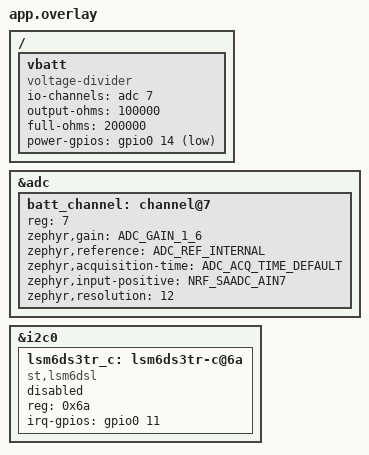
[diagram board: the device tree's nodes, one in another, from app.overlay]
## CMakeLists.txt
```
# SPDX-License-Identifier: Apache-2.0
cmake_minimum_required(VERSION 3.20.0)
find_package(Zephyr REQUIRED HINTS $ENV{ZEPHYR_BASE})
project(SmartBridge)

target_sources(app PRIVATE src/main.c)

if(CONFIG_SMARTBRIDGE_ANT)
  target_sources(app PRIVATE src/ant_bpwr.c)
  target_sources(app PRIVATE src/ant_lev.c)
endif()
```

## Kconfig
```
mainmenu "SmartBridge"

config SMARTBRIDGE_ANT
    bool "Enable ANT+ Bicycle Power (requires ANT+ Adopter access)"
    depends on ANT
    help
      Enable ANT+ Bicycle Power transmission alongside BLE.
      Requires ANT+ Adopter registration at thisisant.com and
      access to the sdk-ant repository.

source "Kconfig.zephyr"
```

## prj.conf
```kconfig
# ANT disabled — BLE only build
CONFIG_SMARTBRIDGE_ANT=n

# ====================== USB Serial ======================
CONFIG_USB_CDC_ACM=y
CONFIG_USB_DEVICE_STACK=y
CONFIG_UART_LINE_CTRL=y
CONFIG_UART_CONSOLE=y

# ====================== Bootloader ======================
# DISABLE MCUBOOT - much simpler for now
# CONFIG_BOOTLOADER_MCUBOOT=n

# ====================== Bluetooth ======================
CONFIG_BT=y
CONFIG_BT_PERIPHERAL=y
CONFIG_BT_MAX_CONN=2
CONFIG_BT_GATT_DYNAMIC_DB=y
CONFIG_BT_DEVICE_NAME="SmartBridge"
CONFIG_BT_DEVICE_NAME_DYNAMIC=y

# ====================== Services ======================
CONFIG_BT_DIS=y
CONFIG_BT_DIS_MANUF="Nilogax"
CONFIG_BT_DIS_MODEL="SmartBridge"
CONFIG_BT_DIS_FW_REV=y
CONFIG_BT_DIS_FW_REV_STR="0.9.2"
CONFIG_BT_BAS=y

# ====================== Peripherals ======================
CONFIG_ADC=y
CONFIG_I2C=y
CONFIG_GPIO=y

# ====================== Logging ======================
CONFIG_PRINTK=y
CONFIG_LOG=y
CONFIG_LOG_DEFAULT_LEVEL=2

# ====================== Memory ======================
CONFIG_MAIN_STACK_SIZE=4096
CONFIG_SYSTEM_WORKQUEUE_STACK_SIZE=4096
CONFIG_HEAP_MEM_POOL_SIZE=8192

CONFIG_LSM6DSL=n
CONFIG_LSM6DSO=n
CONFIG_LSM6DS0=n
```

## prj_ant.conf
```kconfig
# ANT enabled
CONFIG_ANT=y
CONFIG_ANT_EVALUATION_KEY=y
CONFIG_SMARTBRIDGE_ANT=y
CONFIG_ANT_BPWR=y
CONFIG_ANT_KEY_MANAGER=y
CONFIG_ANT_CHANNEL_CONFIG=y

# ====================== USB Serial ======================
CONFIG_USB_CDC_ACM=y
CONFIG_USB_DEVICE_STACK=y
CONFIG_UART_LINE_CTRL=y
CONFIG_UART_CONSOLE=y

# ====================== Bootloader ======================
# DISABLE MCUBOOT - much simpler for now
# CONFIG_BOOTLOADER_MCUBOOT=n

# ====================== Bluetooth ======================
CONFIG_BT=y
CONFIG_BT_PERIPHERAL=y
CONFIG_BT_MAX_CONN=2
CONFIG_BT_GATT_DYNAMIC_DB=y
CONFIG_BT_DEVICE_NAME="SmartBridge"
CONFIG_BT_DEVICE_NAME_DYNAMIC=y

# ====================== Services ======================
CONFIG_BT_DIS=y
CONFIG_BT_DIS_MANUF="Nilogax"
CONFIG_BT_DIS_MODEL="SmartBridge"
CONFIG_BT_DIS_FW_REV=y
CONFIG_BT_DIS_FW_REV_STR="0.9.2"
CONFIG_BT_BAS=y

# ====================== Peripherals ======================
CONFIG_ADC=y
CONFIG_I2C=y
CONFIG_GPIO=y

# ====================== Logging ======================
CONFIG_PRINTK=y
CONFIG_LOG=y
CONFIG_LOG_DEFAULT_LEVEL=2

# ====================== Memory ======================
CONFIG_MAIN_STACK_SIZE=4096
CONFIG_SYSTEM_WORKQUEUE_STACK_SIZE=4096
CONFIG_HEAP_MEM_POOL_SIZE=8192

CONFIG_LSM6DSL=n
CONFIG_LSM6DSO=n
CONFIG_LSM6DS0=n
```

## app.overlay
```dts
/ {
    vbatt: vbatt {
        compatible = "voltage-divider";
        io-channels = <&adc 7>;
        output-ohms = <100000>;
        full-ohms = <200000>;
        power-gpios = <&gpio0 14 GPIO_ACTIVE_LOW>;
    };
};

&adc {
    status = "okay";
    #address-cells = <1>;
    #size-cells = <0>;

    batt_channel: channel@7 {
        reg = <7>;
        zephyr,gain = "ADC_GAIN_1_6";
        zephyr,reference = "ADC_REF_INTERNAL";
        zephyr,acquisition-time = <ADC_ACQ_TIME_DEFAULT>;
        zephyr,input-positive = <NRF_SAADC_AIN7>;
        zephyr,resolution = <12>;
    };
};

&i2c0 {
    status = "okay";
    lsm6ds3tr_c: lsm6ds3tr-c@6a {
        compatible = "st,lsm6dsl";
        reg = <0x6a>;
        irq-gpios = <&gpio0 11 GPIO_ACTIVE_HIGH>;
    };
};

&lsm6ds3tr_c {
    status = "disabled";
};
```

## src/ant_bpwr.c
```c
/*
 * SmartBridge ANT+ Bicycle Power sensor
 */

#ifdef CONFIG_SMARTBRIDGE_ANT

#include <zephyr/kernel.h>
#include <zephyr/logging/log.h>

#include <ant_interface.h>
#include <ant_key_manager.h>
#include <ant_profiles/bpwr/ant_bpwr.h>
#include "ant_common_page_82.h"
#include "version.h"

LOG_MODULE_REGISTER(smartbridge_ant, LOG_LEVEL_INF);

/* ── Channel configuration ───────────────────────────────────────────────── */
#define ANT_BPWR_CHANNEL_NUM    0
#define ANT_BPWR_NETWORK_NUM    0
#define ANT_BPWR_TRANS_TYPE     5

#define ANT_DEVICE_NUMBER_DEFAULT  49

#define ANT_HW_VERSION          1
#define ANT_MFG_ID              255
#define ANT_MODEL_NUM           1
#define ANT_SW_VERSION_MAJOR    10*FW_VERSION_MAJOR + FW_VERSION_MINOR
#define ANT_SW_VERSION_MINOR    FW_VERSION_PATCH
#define ANT_SERIAL_NUM          ((uint32_t)(NRF_FICR->DEVICEADDR[0]))

/*
 * ── Page 82 interleave ────────────────────────────────────────────────────
*/
#define ANT_P82_INTERLEAVE_COUNT   122u

/* Battery voltage thresholds in mV */
#define BATT_THRESH_LOW_MV      3500u
#define BATT_THRESH_CRIT_MV     3200u

/* ── Module state ────────────────────────────────────────────────────────── */
static ant_bpwr_profile_t        bpwr;
static ant_common_page82_data_t  s_page82     = DEFAULT_ANT_COMMON_page82();
static uint32_t                  s_tx_count   = 0;

/* Forward declarations needed by config macros */
static void ant_bpwr_evt_handler(ant_bpwr_profile_t *p_profile,
                                  ant_bpwr_evt_t event);
static void ant_bpwr_calib_handler(ant_bpwr_profile_t *p_profile,
                                    ant_bpwr_page1_data_t *p_page1);

BPWR_SENS_CHANNEL_CONFIG_DEF(bpwr,
    ANT_BPWR_CHANNEL_NUM,
    ANT_BPWR_TRANS_TYPE,
    ANT_DEVICE_NUMBER_DEFAULT,
    ANT_BPWR_NETWORK_NUM);

BPWR_SENS_PROFILE_CONFIG_DEF(bpwr,
    TORQUE_NONE,
    ant_bpwr_calib_handler,
    ant_bpwr_evt_handler);

/* ── Profile event handler ───────────────────────────────────────────────── */
static void ant_bpwr_evt_handler(ant_bpwr_profile_t *p_profile,
                                  ant_bpwr_evt_t event)
{
    ARG_UNUSED(p_profile);
    ARG_UNUSED(event);
}

/* ── Calibration handler ─────────────────────────────────────────────────── */
static void ant_bpwr_calib_handler(ant_bpwr_profile_t *p_profile,
                                    ant_bpwr_page1_data_t *p_page1)
{
    switch (p_page1->calibration_id) {
    case ANT_BPWR_CALIB_ID_MANUAL:
    case ANT_BPWR_CALIB_ID_AUTO:
        p_profile->BPWR_PROFILE_calibration_id     = ANT_BPWR_CALIB_ID_MANUAL_SUCCESS;
        p_profile->BPWR_PROFILE_general_calib_data = 0;
        break;
    default:
        break;
    }
}

/* ── ANT event callback ──────────────────────────────────────────────────── */
static void ant_evt_handler(ant_evt_t *p_ant_evt)
{
    if (p_ant_evt->channel != ANT_BPWR_CHANNEL_NUM) {
        return;
    }

    /*
     * On every ANT_P82_INTERLEAVE_COUNT-th TX event, encode page 82
     * ourselves and skip the library's ant_message_send for that slot.
     */
    if (p_ant_evt->event == EVENT_TX) {
        s_tx_count++;
        if (s_tx_count >= ANT_P82_INTERLEAVE_COUNT) {
            s_tx_count = 0;

            uint8_t buf[ANT_STANDARD_DATA_PAYLOAD_SIZE];
            ant_common_page_82_encode(buf, &s_page82);

            int err = ant_broadcast_message_tx(ANT_BPWR_CHANNEL_NUM,
                                               sizeof(buf), buf);
            if (err) {
                LOG_WRN("Page 82 TX failed (err %d)", err);
            } else {
                LOG_INF("ANT: Page 82 sent (status=%u)", s_page82.battery_status);
            }
            /*
             * Return WITHOUT forwarding to ant_bpwr_sens_evt_handler.
             */
            return;
        }
    }

    /* All other events (including normal EVENT_TX) go to the library */
    ant_bpwr_sens_evt_handler(p_ant_evt, &bpwr);
}

/* ── Public API ──────────────────────────────────────────────────────────── */

int ant_bpwr_setup(void)
{
    int err;

    err = ant_init();
    if (err) {
        LOG_ERR("ant_init failed (err %d)", err);
        return err;
    }
    LOG_INF("ANT version: %s", ANT_VERSION_STRING);

    err = ant_cb_register(ant_evt_handler);
    if (err) {
        LOG_ERR("ant_cb_register failed (err %d)", err);
        return err;
    }

    err = ant_plus_key_set(ANT_BPWR_NETWORK_NUM);
    if (err) {
        LOG_ERR("ant_network_key_set failed (err %d)", err);
        return err;
    }

    err = ant_bpwr_sens_init(&bpwr,
                              BPWR_SENS_CHANNEL_CONFIG(bpwr),
                              BPWR_SENS_PROFILE_CONFIG(bpwr));
    if (err) {
        LOG_ERR("ant_bpwr_sens_init failed (err %d)", err);
        return err;
    }

    uint16_t dev_num = (uint16_t)(NRF_FICR->DEVICEADDR[0] & 0xFFFF);
    ant_channel_id_set(ANT_BPWR_CHANNEL_NUM,
                       dev_num,
                       BPWR_DEVICE_TYPE,
                       ANT_BPWR_TRANS_TYPE);

    bpwr.page_80 = ANT_COMMON_page80(ANT_HW_VERSION,
                                      ANT_MFG_ID,
                                      ANT_MODEL_NUM);
    bpwr.page_81 = ANT_COMMON_page81(ANT_SW_VERSION_MAJOR,
                                      ANT_SW_VERSION_MINOR,
                                      ANT_SERIAL_NUM);

    bpwr.BPWR_PROFILE_auto_zero_status = ANT_BPWR_AUTO_ZERO_OFF;

    err = ant_bpwr_sens_open(&bpwr);
    if (err) {
        LOG_ERR("ant_bpwr_sens_open failed (err %d)", err);
        return err;
    }

    LOG_INF("ANT+ Bicycle Power channel open (device %u)", dev_num);
    return 0;
}

void ant_bpwr_update(uint16_t watts, uint8_t cadence, uint8_t left_pct)
{
    bpwr.BPWR_PROFILE_power_update_event_count++;
    bpwr.BPWR_PROFILE_accumulated_power    += watts;
    bpwr.BPWR_PROFILE_instantaneous_power   = watts;
    bpwr.BPWR_PROFILE_instantaneous_cadence = cadence;

    if (left_pct <= 100) {
        bpwr.BPWR_PROFILE_pedal_power.distribution    = 100u - left_pct;
        bpwr.BPWR_PROFILE_pedal_power.differentiation = 1;
    } else {
        bpwr.page_16.pedal_power.byte = 0xFF;
    }
}

void ant_bpwr_update_battery(uint16_t vbat_mv)
{
    uint8_t coarse = (uint8_t)(vbat_mv / 1000u);
    uint8_t frac   = (uint8_t)(((vbat_mv % 1000u) * 256u) / 1000u);

    uint8_t status;
    if      (vbat_mv < BATT_THRESH_CRIT_MV) { status = ANT_COMMON_PAGE82_BATTERY_STATUS_CRITICAL; }
    else if (vbat_mv < BATT_THRESH_LOW_MV)  { status = ANT_COMMON_PAGE82_BATTERY_STATUS_LOW;      }
    else if (vbat_mv < 3800u)               { status = ANT_COMMON_PAGE82_BATTERY_STATUS_OK;       }
    else if (vbat_mv < 4100u)               { status = ANT_COMMON_PAGE82_BATTERY_STATUS_GOOD;     }
    else                                    { status = ANT_COMMON_PAGE82_BATTERY_STATUS_NEW;      }

    s_page82 = ANT_COMMON_page82(
        0,        /* cumulative_op_time not tracked */
        coarse,
        frac,
        status);

    LOG_INF("Battery: %u mV -> coarse=%u frac=%u", vbat_mv, coarse, frac);
    LOG_INF("Battery status: %u", status);
}

void ant_bpwr_stop(void)
{
    int err = ant_channel_close(ANT_BPWR_CHANNEL_NUM);
    if (err) {
        LOG_WRN("ant_channel_close failed (err %d)", err);
    } else {
        LOG_INF("ANT+ channel closed");
    }
}

void ant_bpwr_start(void)
{
    s_tx_count = 0;
    int err = ant_bpwr_sens_open(&bpwr);
    if (err) {
        LOG_WRN("ant_bpwr_sens_open failed on wake (err %d)", err);
    } else {
        LOG_INF("ANT+ channel reopened");
    }
}

#endif /* CONFIG_SMARTBRIDGE_ANT */
```

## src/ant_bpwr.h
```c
/*
 * SmartBridge ANT+ Bicycle Power interface
 */
#ifndef SMARTBRIDGE_ANT_BPWR_H
#define SMARTBRIDGE_ANT_BPWR_H

#ifdef CONFIG_SMARTBRIDGE_ANT

/**
 * Initialise ANT stack, register the bicycle power sensor channel,
 * and open it. Call once at the top of main() before the main loop.
 * Returns 0 on success, negative error code on failure.
 */
int ant_bpwr_setup(void);

/**
 * Update the transmitted power data. Call every 250 ms alongside
 * the existing BLE send_power() call.
 *
 * @param watts      Instantaneous power (W)
 * @param cadence    Instantaneous cadence (rpm)
 * @param left_pct   Left pedal balance (0-100, >100 = not available)
 */
void ant_bpwr_update(uint16_t watts, uint8_t cadence, uint8_t left_pct);

/**
 * Update ANT+ Page 82 (Battery Status). Call whenever a fresh ADC
 * reading is available — every 60 s is sufficient.
 *
 * @param vbat_mv       Battery voltage in millivolts (e.g. 3700).
 * @param op_time_16s   Cumulative operating time in 16-second units.
 *                      Pass 0 if not tracked.
 */
void ant_bpwr_update_battery(uint16_t vbat_mv);

/**
 * Close the ANT channel. Call from enter_sleep().
 */
void ant_bpwr_stop(void);

/**
 * Re-open the ANT channel. Call from wake_up().
 */
void ant_bpwr_start(void);

#endif /* CONFIG_SMARTBRIDGE_ANT */
#endif /* SMARTBRIDGE_ANT_BPWR_H */
```

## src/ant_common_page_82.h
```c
/*
 * ANT+ Common Page 82 (0x52) - Battery Status
 * Not present in NCS 2.6.0 ANT library.
 *
 * Byte layout:
 *   [0] 0x52  page number
 *   [1] 0xFF  reserved
 *   [2] 0xFF  battery identifier (0xFF = single battery / not used)
 *   [3] op_time bits  0-7
 *   [4] op_time bits  8-15
 *   [5] op_time bits 16-23  (resolution flag NOT used here; kept simple)
 *   [6] fractional voltage  (1/256 V per LSB)
 *   [7] bits 3-0 = coarse voltage (0-14 V; 15 = invalid)
 *       bits 6-4 = battery status
 *       bit    7 = 0 (reserved)
 *
 */
#ifndef ANT_COMMON_PAGE_82_H__
#define ANT_COMMON_PAGE_82_H__

#include <stdint.h>

#ifdef __cplusplus
extern "C" {
#endif

#define ANT_COMMON_PAGE_82  (82u)   ///< Page number (0x52)

/* ── Battery status nibble (bits 6-4 of byte 7) ─────────────────────────── */
#define ANT_COMMON_PAGE82_BATTERY_STATUS_NEW        (1u)
#define ANT_COMMON_PAGE82_BATTERY_STATUS_GOOD       (2u)
#define ANT_COMMON_PAGE82_BATTERY_STATUS_OK         (3u)
#define ANT_COMMON_PAGE82_BATTERY_STATUS_LOW        (4u)
#define ANT_COMMON_PAGE82_BATTERY_STATUS_CRITICAL   (5u)
#define ANT_COMMON_PAGE82_BATTERY_STATUS_INVALID    (7u)

/**
 * @brief Data structure for ANT+ common page 82.
 *
 * coarse_voltage : whole volts (0-14; 15 = invalid)
 * frac_voltage   : fractional volts in units of 1/256 V (0-255)
 *   e.g. 3.9 V → coarse=3, frac=round(0.9×256)=230
 */
typedef struct
{
    uint32_t cumulative_op_time;    ///< Operating time; 0 if not tracked
    uint8_t  coarse_voltage;        ///< Whole volts (0-14; 15 = invalid)
    uint8_t  frac_voltage;          ///< Fractional voltage (1/256 V per LSB)
    uint8_t  battery_status;        ///< ANT_COMMON_PAGE82_BATTERY_STATUS_*
} ant_common_page82_data_t;

/** @brief Zero-initialise page 82 with invalid status. */
#define DEFAULT_ANT_COMMON_page82()         \
    (ant_common_page82_data_t)              \
    {                                       \
        .cumulative_op_time = 0,            \
        .coarse_voltage     = 15,           \
        .frac_voltage       = 0,            \
        .battery_status     = ANT_COMMON_PAGE82_BATTERY_STATUS_INVALID, \
    }

/** @brief Initialise page 82 with specific values. */
#define ANT_COMMON_page82(op_time, coarse, frac, status)    \
    (ant_common_page82_data_t)                              \
    {                                                       \
        .cumulative_op_time = (op_time),                    \
        .coarse_voltage     = (coarse),                     \
        .frac_voltage       = (frac),                       \
        .battery_status     = (status),                     \
    }

/**
 * @brief Encode page 82 into an 8-byte ANT broadcast buffer.
 */
static inline void ant_common_page_82_encode(
        uint8_t * p_buf,
        ant_common_page82_data_t const * p_page_data)
{
    p_buf[0] = ANT_COMMON_PAGE_82;  /* 0x52                          */
    p_buf[1] = 0xFF;                /* reserved                      */
    p_buf[2] = 0xFF;                /* battery identifier: not used  */

    /* Bytes 3-5: 24-bit cumulative operating time, little-endian    */
    p_buf[3] = (uint8_t)(p_page_data->cumulative_op_time);
    p_buf[4] = (uint8_t)(p_page_data->cumulative_op_time >> 8);
    p_buf[5] = (uint8_t)(p_page_data->cumulative_op_time >> 16);

    /* Byte 6: fractional voltage                                     */
    p_buf[6] = p_page_data->frac_voltage;

    /* Byte 7: coarse voltage (bits 3-0), status (bits 6-4), bit7=0  */
    p_buf[7] = (uint8_t)(
        (p_page_data->coarse_voltage  & 0x0Fu) |
        ((p_page_data->battery_status & 0x07u) << 4));
}

#ifdef __cplusplus
}
#endif

#endif /* ANT_COMMON_PAGE_82_H__ */
```

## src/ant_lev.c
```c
#ifdef CONFIG_SMARTBRIDGE_ANT

#include <zephyr/kernel.h>
#include <zephyr/logging/log.h>
#include <ant_interface.h>
#include <ant_parameters.h>
#include <ant_host_init.h>
#include <ant_channel_config.h>
#include <ant_key_manager.h>
#include "version.h"

LOG_MODULE_REGISTER(smartbridge_lev, LOG_LEVEL_INF);

#define ANT_LEV_CHANNEL_NUM     1
#define ANT_LEV_NETWORK_NUM     0
#define ANT_LEV_DEVICE_TYPE     0x14u
#define ANT_LEV_TRANS_TYPE      0x05u
#define ANT_LEV_RF_FREQ         0x39u
#define ANT_LEV_MSG_PERIOD      8192u
#define ANT_LEV_EXT_ASSIGN      0x00u

/* Pages 80/81 */
#define ANT_LEV_HW_REVISION     1
#define ANT_LEV_MFG_ID          63          /* Pretend to be Specialized */
#define ANT_LEV_MODEL_NUM       2
#define ANT_LEV_SERIAL_NUM      ((uint32_t)(NRF_FICR->DEVICEADDR[0]))


#define ANT_LEV_NUM_ASSIST_MODES  4u   /* excluding off */

#define COMMON_PAGE_INTERVAL    40u

/* ── Module state ────────────────────────────────────────────────────────── */
static uint8_t  s_soc_pct     = 0;
static uint8_t  s_assist_mode = 0;   /* internal 0-4 */
static uint8_t  s_assist_pct  = 0;
static uint32_t s_odometer    = 0;   /* 0.01 km units, 24-bit               */
static uint16_t s_speed       = 0;   /* 0.1 km/h units, 12-bit              */
static uint16_t s_range_km    = 0;   /* whole km; 0 = unknown               */
static uint32_t s_msg_count   = 0;

static void lev_ant_evt_handler(ant_evt_t *p_ant_evt);

static const ant_channel_config_t s_lev_channel_cfg = {
    .channel_number    = ANT_LEV_CHANNEL_NUM,
    .channel_type      = CHANNEL_TYPE_MASTER,
    .ext_assign        = ANT_LEV_EXT_ASSIGN,
    .rf_freq           = ANT_LEV_RF_FREQ,
    .transmission_type = ANT_LEV_TRANS_TYPE,
    .device_type       = ANT_LEV_DEVICE_TYPE,
    .device_number     = 0,
    .channel_period    = ANT_LEV_MSG_PERIOD,
    .network_number    = ANT_LEV_NETWORK_NUM,
};

/* ── Travel mode byte helper ─────────────────────────────────────────────── */

static inline uint8_t travel_mode_byte(void)
{
    uint8_t mode = s_assist_mode < 5u ? s_assist_mode : 4u;
    return (uint8_t)((mode & 0x07u) << 3);
}

/* ── Page encoders ───────────────────────────────────────────────────────── */

/*
 * Page 1 – Speed & System Information 1 (Table 5-2)
 *
 * Byte 0: 0x01
 * Byte 1: Temperature state — 0x00 = unknown
 * Byte 2: Travel mode state (Table 5-4)
 * Byte 3: System state — 0x00 = no lights/throttle/signals
 * Byte 4: Gear state   — 0x00 = no gears
 * Byte 5: Error message — 0x00 = no error
 * Byte 6: Speed LSB (12-bit, 0.1 km/h units)
 * Byte 7: Speed MSN (bits 3-0) | 0xF0 (reserved bits 7-4 = 0xF per spec)
 */
static void encode_page1(uint8_t *buf)
{
    uint16_t spd = s_speed & 0x0FFFu;
    buf[0] = 0x01u;
    buf[1] = 0x00u;           /* temperature unknown                        */
    buf[2] = travel_mode_byte();
    buf[3] = 0x00u;           /* system state: nothing supported            */
    buf[4] = 0x00u;           /* gear state: no gears                       */
    buf[5] = 0x00u;           /* no error                                   */
    buf[6] = (uint8_t)(spd & 0xFFu);
    buf[7] = (uint8_t)(0xF0u | ((spd >> 8) & 0x0Fu));
}

/*
 * Page 2 – Speed & Distance Information (Table 5-8)
 *
 * Byte 0: 0x02
 * Byte 1-3: Odometer (24-bit LE, 0.01 km)
 * Byte 4:   Remaining range LSB (12-bit km; 0x000 = unknown)
 * Byte 5:   Remaining range MSN (bits 3-0) | 0xF0 (reserved)
 * Byte 6:   Speed LSB (0.1 km/h, 12-bit)
 * Byte 7:   Speed MSN | 0xF0
 */
static void encode_page2(uint8_t *buf)
{
    uint32_t odo  = s_odometer & 0xFFFFFFu;
    uint16_t rng  = s_range_km & 0x0FFFu;
    uint16_t spd  = s_speed    & 0x0FFFu;
    buf[0] = 0x02u;
    buf[1] = (uint8_t)(odo & 0xFFu);
    buf[2] = (uint8_t)((odo >> 8) & 0xFFu);
    buf[3] = (uint8_t)((odo >> 16) & 0xFFu);
    buf[4] = (uint8_t)(rng & 0xFFu);
    buf[5] = (uint8_t)(0xF0u | ((rng >> 8) & 0x0Fu));
    buf[6] = (uint8_t)(spd & 0xFFu);
    buf[7] = (uint8_t)(0xF0u | ((spd >> 8) & 0x0Fu));
}

/*
 * Page 3 – Speed & System Information 2 (Table 5-10)
 *
 * Byte 0: 0x03
 * Byte 1: Battery SOC — bits 6-0 = %, bit 7 = empty warning
 * Byte 2: Travel mode state (same as page 1)
 * Byte 3: System state — 0x00
 * Byte 4: Gear state   — 0x00
 * Byte 5: % Assist     — 0xFF = unknown, or actual value 0-100
 * Byte 6: Speed LSB (0.1 km/h, 12-bit)
 * Byte 7: Speed MSN | 0xF0
 */
static void encode_page3(uint8_t *buf)
{
    uint8_t soc = s_soc_pct & 0x7Fu;   /* bit 7 = empty warning (set if <5%) */
    if (s_soc_pct < 5u) {
        soc |= 0x80u;
    }
    uint16_t spd = s_speed & 0x0FFFu;
    buf[0] = 0x03u;
    buf[1] = soc;
    buf[2] = travel_mode_byte();
    buf[3] = 0x00u;
    buf[4] = 0x00u;
    buf[5] = s_assist_pct;
    buf[6] = (uint8_t)(spd & 0xFFu);
    buf[7] = (uint8_t)(0xF0u | ((spd >> 8) & 0x0Fu));
}

/*
 * Page 5 – LEV Capabilities (Table 5-12)
 *
 * Byte 0: 0x05
 * Byte 1: 0xFF reserved
 * Byte 2: Travel modes supported — bits 5-3 = num assist, bits 2-0 = num regen
 * Byte 3: Wheel circumference LSB — 0x00 = unknown
 * Byte 4: Wheel circ MSN (bits 3-0) = 0, reserved bits 7-4 = 0xF
 * Bytes 5-7: 0xFF
 */
static void encode_page5(uint8_t *buf)
{
    buf[0] = 0x05u;
    buf[1] = 0xFFu;
    buf[2] = (uint8_t)((ANT_LEV_NUM_ASSIST_MODES & 0x07u) << 3); /* 4 assist, 0 regen */
    buf[3] = 0x00u;   /* wheel circumference unknown                        */
    buf[4] = 0xF0u;   /* MSN=0 (unknown), reserved=0xF                     */
    buf[5] = 0xFFu;
    buf[6] = 0xFFu;
    buf[7] = 0xFFu;
}

/*
 * Page 80 – Manufacturer info (Table 5-17)
 */
static void encode_page80(uint8_t *buf)
{
    buf[0] = 0x50u;
    buf[1] = 0xFFu;
    buf[2] = 0xFFu;
    buf[3] = ANT_LEV_HW_REVISION;
    buf[4] = (uint8_t)(ANT_LEV_MFG_ID & 0xFFu);
    buf[5] = (uint8_t)(ANT_LEV_MFG_ID >> 8);
    buf[6] = (uint8_t)(ANT_LEV_MODEL_NUM & 0xFFu);
    buf[7] = (uint8_t)(ANT_LEV_MODEL_NUM >> 8);
}

/*
 * Page 81 – Product info (Table 5-18)
 */
static void encode_page81(uint8_t *buf)
{
    buf[0] = 0x51u;
    buf[1] = 0xFFu;
    buf[2] = 0xFFu;
    buf[3] = FW_VERSION_MINOR;
    buf[4] = (uint8_t)(ANT_LEV_SERIAL_NUM);
    buf[5] = (uint8_t)(ANT_LEV_SERIAL_NUM >> 8);
    buf[6] = (uint8_t)(ANT_LEV_SERIAL_NUM >> 16);
    buf[7] = (uint8_t)(ANT_LEV_SERIAL_NUM >> 24);
}

/* ── TX rotation ─────────────────────────────────────────────────────────── */
static void lev_send_next(void)
{
    uint8_t buf[ANT_STANDARD_DATA_PAYLOAD_SIZE];
    uint8_t slot = (uint8_t)(s_msg_count % 4u);

    switch (slot) {
    case 0:
        encode_page1(buf);
        break;
    case 1:
        encode_page2(buf);
        break;
    case 2:
        encode_page3(buf);
        break;
    case 3:
    default:
        /*
         * 4th slot rotates: page 5 normally, page 80 every 40 messages,
         * page 81 every 80 messages, then reset.
         * s_msg_count is the count of the message about to be sent (pre-increment).
         */
        if (s_msg_count == COMMON_PAGE_INTERVAL - 1u) {
            encode_page80(buf);
        } else if (s_msg_count == COMMON_PAGE_INTERVAL * 2u - 1u) {
            encode_page81(buf);
        } else {
            encode_page5(buf);
        }
        break;
    }

    s_msg_count++;
    if (s_msg_count >= COMMON_PAGE_INTERVAL * 2u) {
        s_msg_count = 0u;
    }

    int err = ant_broadcast_message_tx(ANT_LEV_CHANNEL_NUM, sizeof(buf), buf);
    if (err) {
        LOG_WRN("LEV TX failed (err %d)", err);
    }
}

/* ── Page 16 decoder (Display → LEV) ────────────────────────────────────── */
/*
 * Page 16 – Display Data (Table 5-14)
*
 * Byte 0: 0x10
 * Byte 1: Wheel circumference LSB  (0xFF = not set by display)
 * Byte 2: Wheel circ MSN / reserved
 * Byte 3: Travel mode (Table 5-4 bits 5-0); 0xFF = not set
 * Byte 4: Display command LSB
 * Byte 5: Display command MSB
 * Byte 6: Manufacturer ID LSB
 * Byte 7: Manufacturer ID MSB
 */
static void handle_page16(const uint8_t *buf)
{
    uint8_t travel_mode = buf[3];
    if (travel_mode == 0xFFu) {
        return;
    }

    /* Extract assist level from bits 5-3 and clamp to our 0-4 range */
    uint8_t requested = (travel_mode >> 3) & 0x07u;
    if (requested > 4u) requested = 4u;
    s_assist_mode = requested;
    LOG_INF("Page 16: display requested assist %u", requested);
}

static void lev_ant_evt_handler(ant_evt_t *p_ant_evt)
{
    if (p_ant_evt->channel != ANT_LEV_CHANNEL_NUM) {
        return;
    }

    switch (p_ant_evt->event) {
    case EVENT_TX:
        lev_send_next();
        break;

    case EVENT_RX:
        /*
         * The Garmin may send page 16 as an acknowledged message on the
         * reverse channel. The payload is in p_ant_evt->message.ANT_MESSAGE_aucPayload.
         */
        if (p_ant_evt->message.ANT_MESSAGE_aucPayload[0] == 0x10u) {
            handle_page16(p_ant_evt->message.ANT_MESSAGE_aucPayload);
        }
        break;

    case EVENT_RX_FAIL:
        /* Normal on a master channel — slave didn't respond, not an error */
        break;

    case EVENT_CHANNEL_CLOSED:
        LOG_INF("LEV channel closed");
        break;

    default:
        break;
    }
}


int ant_lev_setup(void)
{
    int err;

    uint16_t dev_num = (uint16_t)((NRF_FICR->DEVICEADDR[0] & 0xFFFF) ^ 0x0001u);
    if (dev_num == 0u) {
        dev_num = 1u;
    }

    err = ant_cb_register(lev_ant_evt_handler);
    if (err) {
        LOG_ERR("ant_cb_register (LEV) failed (err %d)", err);
        return err;
    }

    ant_channel_config_t cfg = s_lev_channel_cfg;
    cfg.device_number = dev_num;

    err = ant_channel_init(&cfg);
    if (err) {
        LOG_ERR("ant_channel_init (LEV) failed (err %d)", err);
        return err;
    }

    /* Seed TX buffer with page 1 before opening */
    uint8_t buf[ANT_STANDARD_DATA_PAYLOAD_SIZE];
    encode_page1(buf);
    err = ant_broadcast_message_tx(ANT_LEV_CHANNEL_NUM, sizeof(buf), buf);
    if (err) {
        LOG_ERR("LEV initial TX failed (err %d)", err);
        return err;
    }

    err = ant_channel_open(ANT_LEV_CHANNEL_NUM);
    if (err) {
        LOG_ERR("ant_channel_open (LEV) failed (err %d)", err);
        return err;
    }

    LOG_INF("ANT+ LEV channel open (device %u, mfg %u)", dev_num, ANT_LEV_MFG_ID);
    return 0;
}

void ant_lev_update(uint8_t battery_soc_pct, uint8_t assist_mode, uint8_t assist_pct,
                    uint32_t odometer_cm, uint16_t speed_dmkh, uint16_t range_km)
{
    s_soc_pct     = (battery_soc_pct <= 100u) ? battery_soc_pct : 100u;
    s_assist_mode = assist_mode;
    s_assist_pct  = assist_pct;
    s_odometer    = odometer_cm  & 0xFFFFFFu;
    s_speed       = speed_dmkh   & 0x0FFFu;
    s_range_km    = range_km     & 0x0FFFu;
}

void ant_lev_stop(void)
{
    int err = ant_channel_close(ANT_LEV_CHANNEL_NUM);
    if (err) {
        LOG_WRN("ant_channel_close (LEV) failed (err %d)", err);
    } else {
        LOG_INF("ANT+ LEV channel closed");
    }
}

void ant_lev_start(void)
{
    s_msg_count = 0;

    uint8_t buf[ANT_STANDARD_DATA_PAYLOAD_SIZE];
    encode_page1(buf);
    ant_broadcast_message_tx(ANT_LEV_CHANNEL_NUM, sizeof(buf), buf);

    int err = ant_channel_open(ANT_LEV_CHANNEL_NUM);
    if (err) {
        LOG_WRN("ant_channel_open (LEV) failed on wake (err %d)", err);
    } else {
        LOG_INF("ANT+ LEV channel reopened");
    }
}

#endif /* CONFIG_SMARTBRIDGE_ANT */
```

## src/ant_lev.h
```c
#ifndef SMARTBRIDGE_ANT_LEV_H
#define SMARTBRIDGE_ANT_LEV_H

#ifdef CONFIG_SMARTBRIDGE_ANT

#include <stdint.h>

/**
 * Initialise and open the ANT+ LEV sensor channel.
 * Call once after ant_bpwr_setup().
 * Returns 0 on success, negative error code on failure.
 */
int ant_lev_setup(void);

/**
 * Update LEV data. Call whenever values change (e.g. every 750 ms).
 *
 * @param battery_soc_pct   Battery state of charge 0-100 %
 * @param assist_mode       Internal assist level 0-4
 * @param assist_pct        Assistance level 0-100 % (motor / total power)
 * @param odometer_cm       Odometer in 0.01 km units (metres / 10), 24-bit
 * @param speed_dmkh        Speed in 0.1 km/h units (0.01 km/h value / 10), 12-bit
 * @param range_km          Estimated remaining range in whole km; 0 = unknown
 */
void ant_lev_update(uint8_t battery_soc_pct, uint8_t assist_mode, uint8_t assist_pct,
                    uint32_t odometer_cm, uint16_t speed_dmkh, uint16_t range_km);

/**
 * Close the LEV channel. Call from enter_sleep().
 */
void ant_lev_stop(void);

/**
 * Re-open the LEV channel. Call from wake_up().
 */
void ant_lev_start(void);

#endif /* CONFIG_SMARTBRIDGE_ANT */
#endif /* SMARTBRIDGE_ANT_LEV_H */
```

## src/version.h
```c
#pragma once
#define FW_VERSION_MAJOR 0
#define FW_VERSION_MINOR 9
#define FW_VERSION_PATCH 6
```
